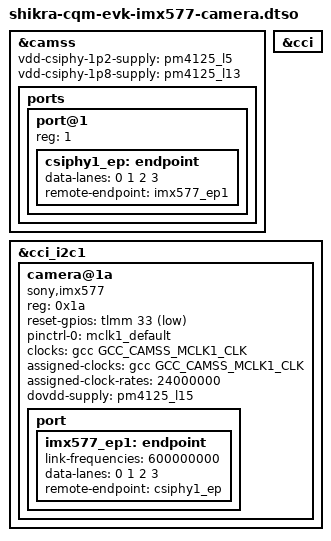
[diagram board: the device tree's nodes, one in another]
// SPDX-License-Identifier: BSD-3-Clause
/*
 * Copyright (c) Qualcomm Technologies, Inc. and/or its subsidiaries.
 */

/dts-v1/;
/plugin/;

#include <dt-bindings/clock/qcom,shikra-gcc.h>
#include <dt-bindings/gpio/gpio.h>

&camss {
	vdd-csiphy-1p2-supply = <&pm4125_l5>;
	vdd-csiphy-1p8-supply = <&pm4125_l13>;

	status = "okay";

	ports {
		#address-cells = <1>;
		#size-cells = <0>;

		port@1 {
			reg = <1>;

			csiphy1_ep: endpoint {
				data-lanes = <0 1 2 3>;
				remote-endpoint = <&imx577_ep1>;
			};
		};
	};
};

&cci {
	status = "okay";
};

&cci_i2c1 {
	#address-cells = <1>;
	#size-cells = <0>;

	camera@1a {
		compatible = "sony,imx577";
		reg = <0x1a>;

		reset-gpios = <&tlmm 33 GPIO_ACTIVE_LOW>;
		pinctrl-0 = <&mclk1_default>;
		pinctrl-names = "default";

		clocks = <&gcc GCC_CAMSS_MCLK1_CLK>;
		assigned-clocks = <&gcc GCC_CAMSS_MCLK1_CLK>;
		assigned-clock-rates = <24000000>;

		dovdd-supply = <&pm4125_l15>;

		port {
			imx577_ep1: endpoint {
				link-frequencies = /bits/ 64 <600000000>;
				data-lanes = <0 1 2 3>;
				remote-endpoint = <&csiphy1_ep>;
			};
		};
	};
};
